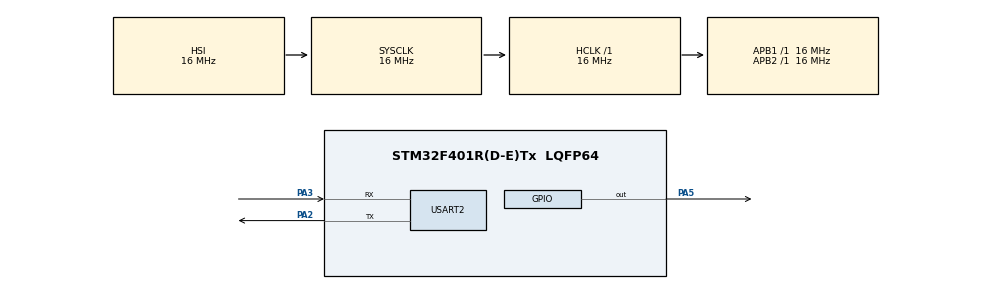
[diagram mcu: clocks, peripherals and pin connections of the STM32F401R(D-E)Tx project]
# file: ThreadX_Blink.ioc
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Mcu.Family=STM32F4
Mcu.Name=STM32F401R(D-E)Tx
Mcu.Package=LQFP64
NVIC.PriorityGroup=NVIC_PRIORITYGROUP_4
NVIC.TIM5_IRQn=true\:15\:0\:false\:false\:true\:false\:false\:true\:true
NVIC.TimeBase=TIM5_IRQn
NVIC.TimeBaseIP=TIM5
NVIC.USART2_IRQn=true\:0\:0\:false\:false\:true\:false\:true\:true\:true
PA2.Mode=Asynchronous
PA2.Signal=USART2_TX
PA3.Mode=Asynchronous
PA3.Signal=USART2_RX
PA5.Signal=GPIO_Output
ProjectManager.HeapSize=0x200
ProjectManager.StackSize=0x400
ProjectManager.TargetToolchain=STM32CubeIDE
RCC.48MHZClocksFreq_Value=48000000
RCC.AHBFreq_Value=16000000
RCC.APB1Freq_Value=16000000
RCC.APB1TimFreq_Value=16000000
RCC.APB2Freq_Value=16000000
RCC.APB2TimFreq_Value=16000000
RCC.CortexFreq_Value=16000000
RCC.HCLKFreq_Value=16000000
RCC.HSE_VALUE=25000000
RCC.HSI_VALUE=16000000
RCC.LSE_VALUE=32768
RCC.SYSCLKFreq_VALUE=16000000
RCC.VCOOutputFreq_Value=192000000
STMicroelectronics.X-CUBE-AZRTOS-F4.1.1.0.ThreadXCcRTOSJjThreadXJjCore=true
STMicroelectronics.X-CUBE-AZRTOS-F4.1.1.0_IsAnAzureRtosMw=true
USART2.VirtualMode=VM_ASYNC
VP_STMicroelectronics.X-CUBE-AZRTOS-F4_VS_RTOSJjThreadX_6.1.10_1.1.0.Mode=RTOSJjThreadX
VP_SYS_VS_tim5.Mode=TIM5
board=custom

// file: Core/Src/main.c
/* USER CODE BEGIN Header */
/**
  ******************************************************************************
  * @file           : main.c
  * @brief          : Main program body
  ******************************************************************************
  * @attention
  *
  * Copyright (c) 2025 STMicroelectronics.
  * All rights reserved.
  *
  * This software is licensed under terms that can be found in the LICENSE file
  * in the root directory of this software component.
  * If no LICENSE file comes with this software, it is provided AS-IS.
  *
  ******************************************************************************
  */
/* USER CODE END Header */
#include "app_threadx.h"
#include "main.h"

UART_HandleTypeDef huart2;

void SystemClock_Config(void);
static void MX_GPIO_Init(void);
static void MX_USART2_UART_Init(void);

/* USER CODE BEGIN 0 */
void debug_message(const char *message)
{
    HAL_UART_Transmit(&huart2, (uint8_t *)message, strlen(message), HAL_MAX_DELAY);
}
/* USER CODE END 0 */

int main(void)
{

  /* MCU Configuration--------------------------------------------------------*/

  /* Reset of all peripherals, Initializes the Flash interface and the Systick. */
  HAL_Init();

  /* Configure the system clock */
  SystemClock_Config();

  /* Initialize all configured peripherals */
  MX_GPIO_Init();
  MX_USART2_UART_Init();
  /* USER CODE BEGIN 2 */
  char message[] = "Hello, Virtual Terminal!\r\n";
  HAL_UART_Transmit(&huart2, (uint8_t *)message, strlen(message), HAL_MAX_DELAY);

  debug_message("System initialized.\r\n");

  /* USER CODE END 2 */
  debug_message("UART test: System is initializing.\r\n");

  MX_ThreadX_Init();

  /* We should never get here as control is now taken by the scheduler */

  /* Infinite loop */
  /* USER CODE BEGIN WHILE */
  debug_message("ThreadX kernel started.\r\n");

  while (1)
  {
    /* USER CODE END WHILE */

  }
}

void SystemClock_Config(void)
{
  RCC_OscInitTypeDef RCC_OscInitStruct = {0};
  RCC_ClkInitTypeDef RCC_ClkInitStruct = {0};

  /** Configure the main internal regulator output voltage
  */
  __HAL_RCC_PWR_CLK_ENABLE();
  __HAL_PWR_VOLTAGESCALING_CONFIG(PWR_REGULATOR_VOLTAGE_SCALE2);

  /** Initializes the RCC Oscillators according to the specified parameters
  * in the RCC_OscInitTypeDef structure.
  */
  RCC_OscInitStruct.OscillatorType = RCC_OSCILLATORTYPE_HSI;
  RCC_OscInitStruct.HSIState = RCC_HSI_ON;
  RCC_OscInitStruct.HSICalibrationValue = RCC_HSICALIBRATION_DEFAULT;
  RCC_OscInitStruct.PLL.PLLState = RCC_PLL_NONE;
  if (HAL_RCC_OscConfig(&RCC_OscInitStruct) != HAL_OK)
  {
    Error_Handler();
  }

  /** Initializes the CPU, AHB and APB buses clocks
  */
  RCC_ClkInitStruct.ClockType = RCC_CLOCKTYPE_HCLK|RCC_CLOCKTYPE_SYSCLK
                              |RCC_CLOCKTYPE_PCLK1|RCC_CLOCKTYPE_PCLK2;
  RCC_ClkInitStruct.SYSCLKSource = RCC_SYSCLKSOURCE_HSI;
  RCC_ClkInitStruct.AHBCLKDivider = RCC_SYSCLK_DIV1;
  RCC_ClkInitStruct.APB1CLKDivider = RCC_HCLK_DIV1;
  RCC_ClkInitStruct.APB2CLKDivider = RCC_HCLK_DIV1;

  if (HAL_RCC_ClockConfig(&RCC_ClkInitStruct, FLASH_LATENCY_0) != HAL_OK)
  {
    Error_Handler();
  }
}

static void MX_USART2_UART_Init(void)
{
    // Make sure GPIOA clock is enabled (if not already done in GPIO_Init)
    __HAL_RCC_GPIOA_CLK_ENABLE();
    // Enable USART2 clock
    __HAL_RCC_USART2_CLK_ENABLE();

    // Small delay after clock enable
    volatile uint32_t dummy = RCC->AHB1ENR;
    (void)dummy;

    // Configure UART GPIO pins
    GPIO_InitTypeDef GPIO_InitStruct = {0};
    GPIO_InitStruct.Pin = GPIO_PIN_2|GPIO_PIN_3;  // PA2 (TX) and PA3 (RX)
    GPIO_InitStruct.Mode = GPIO_MODE_AF_PP;       // Alternate function - Push pull
    GPIO_InitStruct.Pull = GPIO_NOPULL;
    GPIO_InitStruct.Speed = GPIO_SPEED_FREQ_LOW;
    GPIO_InitStruct.Alternate = GPIO_AF7_USART2;  // Set alternate function to USART2
    HAL_GPIO_Init(GPIOA, &GPIO_InitStruct);

    // Verify GPIO configuration for PA2 (TX) and PA3 (RX)
    // Check if pins are in alternate function mode (0b10)
    if ((GPIOA->MODER & (3U << (2 * 2))) != (2U << (2 * 2)) ||
        (GPIOA->MODER & (3U << (3 * 2))) != (2U << (3 * 2))) {
        // Set PA2 and PA3 to alternate function mode
        GPIOA->MODER &= ~((3U << (2 * 2)) | (3U << (3 * 2)));
        GPIOA->MODER |= (2U << (2 * 2)) | (2U << (3 * 2));
    }

    // Verify alternate function configuration
    if ((GPIOA->AFR[0] & (0xF << (2 * 4))) != (7U << (2 * 4)) ||
        (GPIOA->AFR[0] & (0xF << (3 * 4))) != (7U << (3 * 4))) {
        // Set alternate function 7 (USART2) for PA2 and PA3
        GPIOA->AFR[0] &= ~((0xF << (2 * 4)) | (0xF << (3 * 4)));
        GPIOA->AFR[0] |= (7U << (2 * 4)) | (7U << (3 * 4));
    }

    // Configure UART
    huart2.Instance = USART2;
    huart2.Init.BaudRate = 9600;
    huart2.Init.WordLength = UART_WORDLENGTH_8B;
    huart2.Init.StopBits = UART_STOPBITS_1;
    huart2.Init.Parity = UART_PARITY_NONE;
    huart2.Init.Mode = UART_MODE_TX;
    huart2.Init.HwFlowCtl = UART_HWCONTROL_NONE;
    huart2.Init.OverSampling = UART_OVERSAMPLING_16;
    if (HAL_UART_Init(&huart2) != HAL_OK)
    {
        Error_Handler();
    }
}

static void MX_GPIO_Init(void)
{
    GPIO_InitTypeDef GPIO_InitStruct = {0};
    __HAL_RCC_GPIOA_CLK_ENABLE();

    // Small delay after clock enable
    volatile uint32_t dummy = RCC->AHB1ENR;
    (void)dummy;

    HAL_GPIO_WritePin(GPIOA, GPIO_PIN_5, GPIO_PIN_RESET);

    GPIO_InitStruct.Pin = GPIO_PIN_5;
    GPIO_InitStruct.Mode = GPIO_MODE_OUTPUT_PP;
    GPIO_InitStruct.Pull = GPIO_NOPULL;
    GPIO_InitStruct.Speed = GPIO_SPEED_FREQ_LOW;
    HAL_GPIO_Init(GPIOA, &GPIO_InitStruct);

    // Verify configuration
    if ((GPIOA->MODER & (3U << (5 * 2))) != (1U << (5 * 2))) {
        GPIOA->MODER &= ~(3U << (5 * 2));
        GPIOA->MODER |= (1U << (5 * 2));
    }
}

void HAL_TIM_PeriodElapsedCallback(TIM_HandleTypeDef *htim)
{
  if (htim->Instance == TIM5) {
    HAL_IncTick();
  }
}

void Error_Handler(void)
{
  __disable_irq();
  while (1)
  {
  }
}
